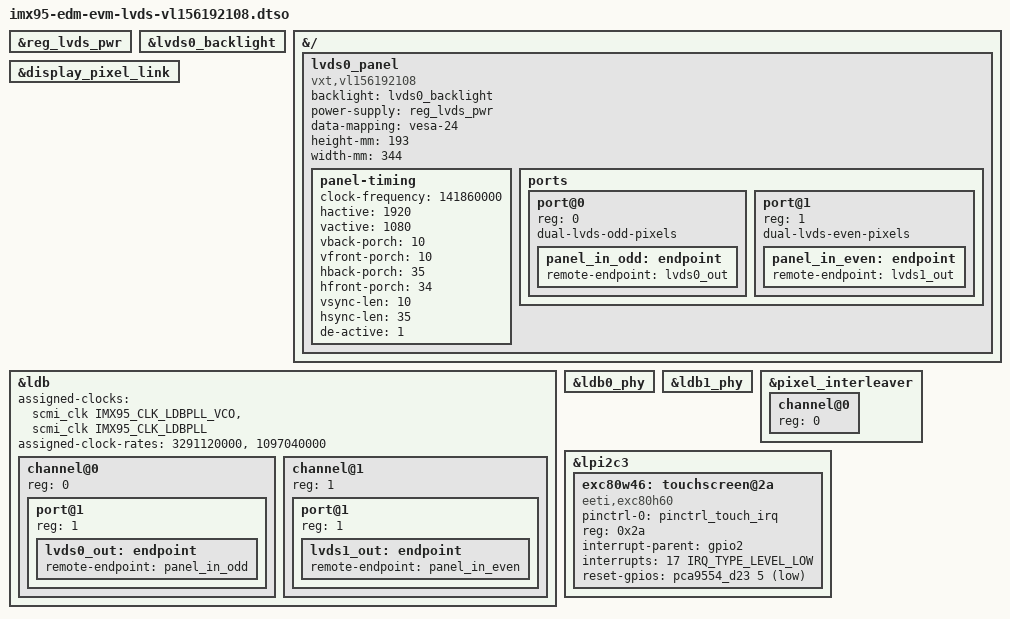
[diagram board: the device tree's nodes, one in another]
// SPDX-License-Identifier: (GPL-2.0 OR MIT)
/*
 * Display Overlay for VXT VL156192108 (15.6" FHD) Dual-LVDS Panel with Touchscreen
 *
 * Copyright 2024 TechNexion Ltd.
 *
 * Author: Richard Hu <richard.hu@technexion.com>
 *
 */

/dts-v1/;
/plugin/;

#include <dt-bindings/gpio/gpio.h>
#include <dt-bindings/interrupt-controller/irq.h>
#include "../imx95-clock.h"

&reg_lvds_pwr { /* LVDS0_VDDEN */
	status = "okay";
};

&lvds0_backlight {
	status = "okay";
};

&{/} {

	lvds0_panel {
		compatible = "vxt,vl156192108", "panel-lvds";
		backlight = <&lvds0_backlight>;
		power-supply = <&reg_lvds_pwr>;
		data-mapping = "vesa-24";
		height-mm = <193>;
		width-mm = <344>;

		panel-timing {
			clock-frequency = <141860000>;
			hactive = <1920>;
			vactive = <1080>;
			vback-porch = <10>;
			vfront-porch = <10>;
			hback-porch = <35>;
			hfront-porch = <34>;
			vsync-len = <10>;
			hsync-len = <35>;
			de-active = <1>;
		};

		ports {
			#address-cells = <1>;
			#size-cells = <0>;

			port@0 {
				reg = <0>;
				dual-lvds-odd-pixels;
				panel_in_odd: endpoint {
					remote-endpoint = <&lvds0_out>;
				};
			};

			port@1 {
				reg = <1>;
				dual-lvds-even-pixels;
				panel_in_even: endpoint {
					remote-endpoint = <&lvds1_out>;
				};
			};
		};
	};
};

&display_pixel_link {
	status = "okay";
};

&ldb {
	#address-cells = <1>;
	#size-cells = <0>;
	assigned-clocks = <&scmi_clk IMX95_CLK_LDBPLL_VCO>,
			  <&scmi_clk IMX95_CLK_LDBPLL>;
	assigned-clock-rates = <3291120000>, <1097040000>;
	status = "okay";

	channel@0 {
		#address-cells = <1>;
		#size-cells = <0>;
		reg = <0>;
		status = "okay";

		port@1 {
			reg = <1>;
			lvds0_out: endpoint {
				remote-endpoint = <&panel_in_odd>;
			};
		};
	};

	channel@1 {
		#address-cells = <1>;
		#size-cells = <0>;
		reg = <1>;
		status = "okay";

		port@1 {
			reg = <1>;
			lvds1_out: endpoint {
				remote-endpoint = <&panel_in_even>;
			};
		};
	};
};

&ldb0_phy {
	status = "okay";
};

&ldb1_phy {
	status = "okay";
};

&pixel_interleaver {
	#address-cells = <1>;
	#size-cells = <0>;
	status = "okay";

	channel@0 {
		reg = <0>;
		status = "okay";
	};
};

/* I2C_C on EDM */
&lpi2c3 {
	status = "okay";
	#address-cells = <1>;
	#size-cells = <0>;

	exc80w46: touchscreen@2a {
		compatible = "eeti,exc80h60";
		pinctrl-names = "default";
		pinctrl-0 = <&pinctrl_touch_irq>;
		reg = <0x2a>;
		interrupt-parent = <&gpio2>;
		interrupts = <17 IRQ_TYPE_LEVEL_LOW>;
		reset-gpios = <&pca9554_d23 5 GPIO_ACTIVE_LOW>;
		status = "okay";
	};
};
